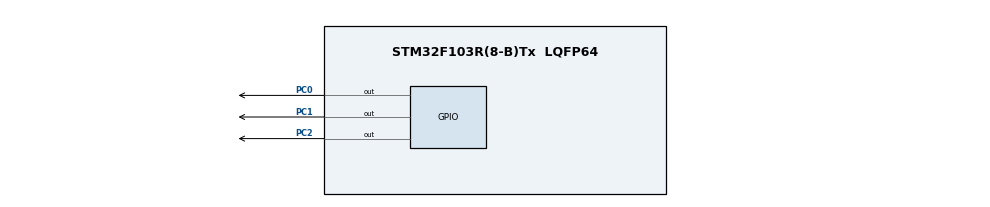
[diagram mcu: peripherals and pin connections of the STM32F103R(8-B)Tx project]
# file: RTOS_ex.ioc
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FREERTOS.Tasks01=defaultTask,24,128,StartDefaultTask,Default,NULL,Dynamic,NULL,NULL;myTask02,8,128,StartTask02,Default,NULL,Dynamic,NULL,NULL;myTask03,8,128,StartTask03,Default,NULL,Dynamic,NULL,NULL
FREERTOS.configUSE_NEWLIB_REENTRANT=1
Mcu.Family=STM32F1
Mcu.Name=STM32F103R(8-B)Tx
Mcu.Package=LQFP64
NVIC.PriorityGroup=NVIC_PRIORITYGROUP_4
NVIC.TIM4_IRQn=true\:15\:0\:false\:false\:true\:false\:false\:true\:true
NVIC.TimeBase=TIM4_IRQn
NVIC.TimeBaseIP=TIM4
PA13.Mode=Serial_Wire
PA13.Signal=SYS_JTMS-SWDIO
PA14.Mode=Serial_Wire
PA14.Signal=SYS_JTCK-SWCLK
PC0.Signal=GPIO_Output
PC1.Signal=GPIO_Output
PC2.Signal=GPIO_Output
ProjectManager.HeapSize=0x200
ProjectManager.StackSize=0x400
ProjectManager.TargetToolchain=CMake
RCC.APB1Freq_Value=8000000
RCC.APB2Freq_Value=8000000
VP_FREERTOS_VS_CMSIS_V2.Mode=CMSIS_V2
VP_SYS_VS_tim4.Mode=TIM4
board=custom

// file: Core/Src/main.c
/* USER CODE BEGIN Header */
/**
 ******************************************************************************
 * @file           : main.c
 * @brief          : Main program body
 ******************************************************************************
 * @attention
 *
 * Copyright (c) 2025 STMicroelectronics.
 * All rights reserved.
 *
 * This software is licensed under terms that can be found in the LICENSE file
 * in the root directory of this software component.
 * If no LICENSE file comes with this software, it is provided AS-IS.
 *
 ******************************************************************************
 */
/* USER CODE END Header */
#include "main.h"
#include "cmsis_os.h"

/* Definitions for defaultTask */
osThreadId_t defaultTaskHandle;
const osThreadAttr_t defaultTask_attributes = {
    .name = "defaultTask",
    .stack_size = 128 * 4,
    .priority = (osPriority_t)osPriorityNormal,
};
/* Definitions for myTask02 */
osThreadId_t myTask02Handle;
const osThreadAttr_t myTask02_attributes = {
    .name = "myTask02",
    .stack_size = 128 * 4,
    .priority = (osPriority_t)osPriorityLow,
};
/* Definitions for myTask03 */
osThreadId_t myTask03Handle;
const osThreadAttr_t myTask03_attributes = {
    .name = "myTask03",
    .stack_size = 128 * 4,
    .priority = (osPriority_t)osPriorityLow,
};

void SystemClock_Config(void);
static void MX_GPIO_Init(void);
void StartDefaultTask(void *argument);
void StartTask02(void *argument);
void StartTask03(void *argument);

int main(void) {

    /* MCU
     * Configuration--------------------------------------------------------*/

    /* Reset of all peripherals, Initializes the Flash interface and the
     * Systick. */
    HAL_Init();

    /* Configure the system clock */
    SystemClock_Config();

    /* Initialize all configured peripherals */
    MX_GPIO_Init();

    /* Init scheduler */
    osKernelInitialize();

    /* Create the thread(s) */
    /* creation of defaultTask */
    defaultTaskHandle =
        osThreadNew(StartDefaultTask, NULL, &defaultTask_attributes);

    /* creation of myTask02 */
    myTask02Handle = osThreadNew(StartTask02, NULL, &myTask02_attributes);

    /* creation of myTask03 */
    myTask03Handle = osThreadNew(StartTask03, NULL, &myTask03_attributes);

    /* Start scheduler */
    osKernelStart();

    /* We should never get here as control is now taken by the scheduler */

    /* Infinite loop */
    while (1) {

    }
}

void SystemClock_Config(void) {
    RCC_OscInitTypeDef RCC_OscInitStruct = {0};
    RCC_ClkInitTypeDef RCC_ClkInitStruct = {0};

    /** Initializes the RCC Oscillators according to the specified parameters
     * in the RCC_OscInitTypeDef structure.
     */
    RCC_OscInitStruct.OscillatorType = RCC_OSCILLATORTYPE_HSI;
    RCC_OscInitStruct.HSIState = RCC_HSI_ON;
    RCC_OscInitStruct.HSICalibrationValue = RCC_HSICALIBRATION_DEFAULT;
    RCC_OscInitStruct.PLL.PLLState = RCC_PLL_NONE;
    if (HAL_RCC_OscConfig(&RCC_OscInitStruct) != HAL_OK) {
        Error_Handler();
    }

    /** Initializes the CPU, AHB and APB buses clocks
     */
    RCC_ClkInitStruct.ClockType = RCC_CLOCKTYPE_HCLK | RCC_CLOCKTYPE_SYSCLK |
                                  RCC_CLOCKTYPE_PCLK1 | RCC_CLOCKTYPE_PCLK2;
    RCC_ClkInitStruct.SYSCLKSource = RCC_SYSCLKSOURCE_HSI;
    RCC_ClkInitStruct.AHBCLKDivider = RCC_SYSCLK_DIV1;
    RCC_ClkInitStruct.APB1CLKDivider = RCC_HCLK_DIV1;
    RCC_ClkInitStruct.APB2CLKDivider = RCC_HCLK_DIV1;

    if (HAL_RCC_ClockConfig(&RCC_ClkInitStruct, FLASH_LATENCY_0) != HAL_OK) {
        Error_Handler();
    }
}

static void MX_GPIO_Init(void) {
    GPIO_InitTypeDef GPIO_InitStruct = {0};

    /* GPIO Ports Clock Enable */
    __HAL_RCC_GPIOC_CLK_ENABLE();
    __HAL_RCC_GPIOA_CLK_ENABLE();

    /*Configure GPIO pin Output Level */
    HAL_GPIO_WritePin(GPIOC, GPIO_PIN_0 | GPIO_PIN_1 | GPIO_PIN_2,
                      GPIO_PIN_RESET);

    /*Configure GPIO pins : PC0 PC1 PC2 */
    GPIO_InitStruct.Pin = GPIO_PIN_0 | GPIO_PIN_1 | GPIO_PIN_2;
    GPIO_InitStruct.Mode = GPIO_MODE_OUTPUT_PP;
    GPIO_InitStruct.Pull = GPIO_NOPULL;
    GPIO_InitStruct.Speed = GPIO_SPEED_FREQ_LOW;
    HAL_GPIO_Init(GPIOC, &GPIO_InitStruct);

}

void StartDefaultTask(void *argument) {
    /* USER CODE BEGIN 5 */
    /* Infinite loop */
    for (;;) {
        HAL_GPIO_TogglePin(GPIOC, GPIO_PIN_0);
        osDelay(128);
    }
    /* USER CODE END 5 */
}

void StartTask02(void *argument) {
    /* USER CODE BEGIN StartTask02 */
    /* Infinite loop */
    for (;;) {
        HAL_GPIO_TogglePin(GPIOC, GPIO_PIN_1);
        osDelay(512);
    }
    /* USER CODE END StartTask02 */
}

void StartTask03(void *argument) {
    /* USER CODE BEGIN StartTask03 */
    /* Infinite loop */
    for (;;) {
        HAL_GPIO_TogglePin(GPIOC, GPIO_PIN_2);
        osDelay(2048);
    }
    /* USER CODE END StartTask03 */
}

void HAL_TIM_PeriodElapsedCallback(TIM_HandleTypeDef *htim) {
    if (htim->Instance == TIM4) {
        HAL_IncTick();
    }
}

void Error_Handler(void) {
    /* USER CODE BEGIN Error_Handler_Debug */
    /* User can add his own implementation to report the HAL error return state
     */
    __disable_irq();
    while (1) {
    }
    /* USER CODE END Error_Handler_Debug */
}

#ifdef USE_FULL_ASSERT
/**
 * @brief  Reports the name of the source file and the source line number
 *         where the assert_param error has occurred.
 * @param  file: pointer to the source file name
 * @param  line: assert_param error line source number
 * @retval None
 */
void assert_failed(uint8_t *file, uint32_t line) {
    /* USER CODE BEGIN 6 */
    /* User can add his own implementation to report the file name and line
       number, ex: printf("Wrong parameters value: file %s on line %d\r\n",
       file, line) */
    /* USER CODE END 6 */
}
#endif /* USE_FULL_ASSERT */
